# DMASS0_INTAGGR_0_INTAGGR_UNMAP register map
Vendor: Texas Instruments
Peripheral module from a debugger description file (folder am243x).
Registers are 64-bit, read-write, reset 0xFFFF unless marked. A register's access mark holds for its fields unless they carry their own. Offsets are as the file gives them; lines under a group give offsets from that group; [hi:lo] are bit positions; {n}, {i} and the like mark numbered series; 'fields as' and 'values as' point back to an identical list; <NAME> marks a mode.

## DMASS0_INTAGGR_0_INTAGGR_UNMAP
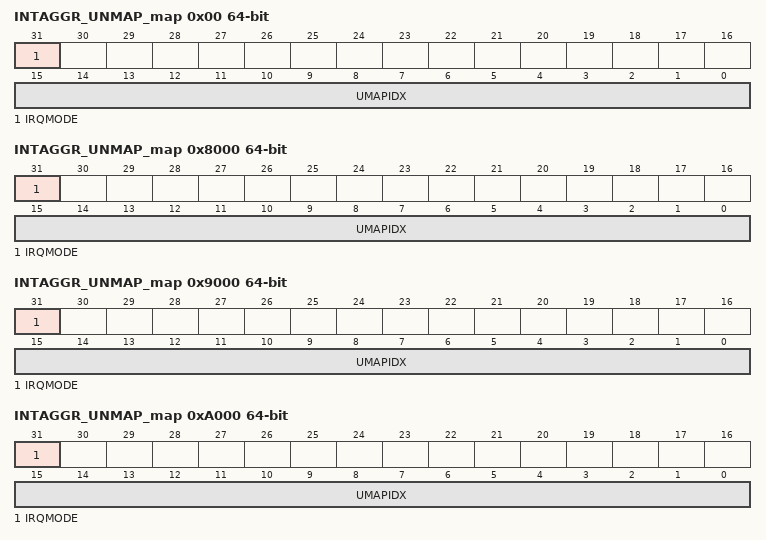
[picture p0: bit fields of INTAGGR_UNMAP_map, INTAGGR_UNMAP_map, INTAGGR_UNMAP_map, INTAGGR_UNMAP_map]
0x00 INTAGGR_UNMAP_map — The Global Event Mapping register controls the egress global event index for this unmapped event. This register may also be optionally used to directly set an interrupt status bit by using the irqmode flag.
  [31] IRQMODE — IRQ Mode Flag. When set, this register act like a mapper with bitnum in 5:0 and regnum in 14:6.
  [15:0] UMAPIDX — Global event index. This field specifies the index of the outgoing global event. Set to 0xFFFF to disable.
0x8000 INTAGGR_UNMAP_map — The Global Event Mapping register controls the egress global event index for this unmapped event. This register may also be optionally used to directly set an interrupt status bit by using the irqmode flag.
  fields as INTAGGR_UNMAP_map
0x9000 INTAGGR_UNMAP_map — The Global Event Mapping register controls the egress global event index for this unmapped event. This register may also be optionally used to directly set an interrupt status bit by using the irqmode flag.
  fields as INTAGGR_UNMAP_map
0xA000 INTAGGR_UNMAP_map — The Global Event Mapping register controls the egress global event index for this unmapped event. This register may also be optionally used to directly set an interrupt status bit by using the irqmode flag.
  fields as INTAGGR_UNMAP_map
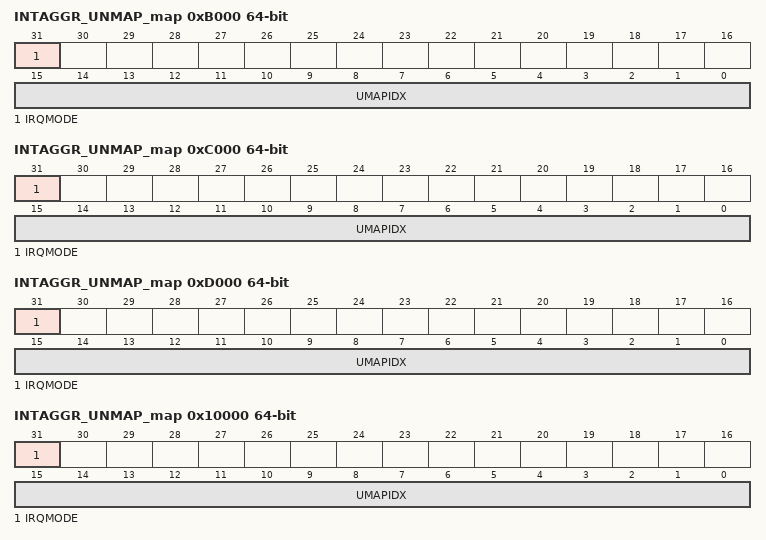
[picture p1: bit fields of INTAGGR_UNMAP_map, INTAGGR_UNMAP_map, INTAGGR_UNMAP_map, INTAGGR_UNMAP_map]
0xB000 INTAGGR_UNMAP_map — The Global Event Mapping register controls the egress global event index for this unmapped event. This register may also be optionally used to directly set an interrupt status bit by using the irqmode flag.
  fields as INTAGGR_UNMAP_map
0xC000 INTAGGR_UNMAP_map — The Global Event Mapping register controls the egress global event index for this unmapped event. This register may also be optionally used to directly set an interrupt status bit by using the irqmode flag.
  fields as INTAGGR_UNMAP_map
0xD000 INTAGGR_UNMAP_map — The Global Event Mapping register controls the egress global event index for this unmapped event. This register may also be optionally used to directly set an interrupt status bit by using the irqmode flag.
  fields as INTAGGR_UNMAP_map
0x10000 INTAGGR_UNMAP_map — The Global Event Mapping register controls the egress global event index for this unmapped event. This register may also be optionally used to directly set an interrupt status bit by using the irqmode flag.
  fields as INTAGGR_UNMAP_map
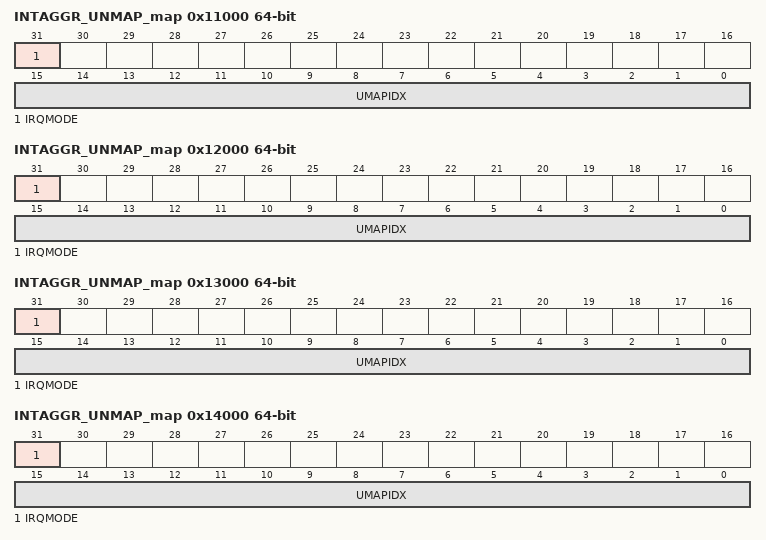
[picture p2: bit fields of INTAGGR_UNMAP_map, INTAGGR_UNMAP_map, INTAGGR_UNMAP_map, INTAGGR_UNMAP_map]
0x11000 INTAGGR_UNMAP_map — The Global Event Mapping register controls the egress global event index for this unmapped event. This register may also be optionally used to directly set an interrupt status bit by using the irqmode flag.
  fields as INTAGGR_UNMAP_map
0x12000 INTAGGR_UNMAP_map — The Global Event Mapping register controls the egress global event index for this unmapped event. This register may also be optionally used to directly set an interrupt status bit by using the irqmode flag.
  fields as INTAGGR_UNMAP_map
0x13000 INTAGGR_UNMAP_map — The Global Event Mapping register controls the egress global event index for this unmapped event. This register may also be optionally used to directly set an interrupt status bit by using the irqmode flag.
  fields as INTAGGR_UNMAP_map
0x14000 INTAGGR_UNMAP_map — The Global Event Mapping register controls the egress global event index for this unmapped event. This register may also be optionally used to directly set an interrupt status bit by using the irqmode flag.
  fields as INTAGGR_UNMAP_map
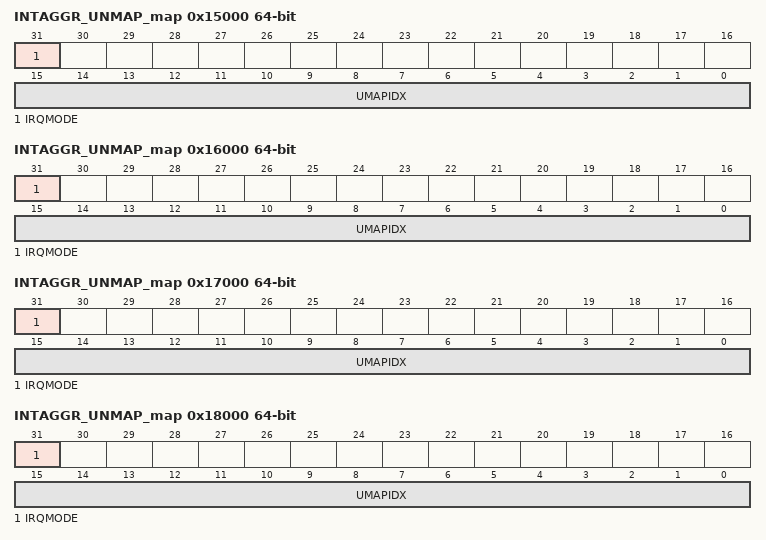
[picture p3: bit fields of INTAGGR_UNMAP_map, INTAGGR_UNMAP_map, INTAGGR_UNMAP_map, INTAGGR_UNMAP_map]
0x15000 INTAGGR_UNMAP_map — The Global Event Mapping register controls the egress global event index for this unmapped event. This register may also be optionally used to directly set an interrupt status bit by using the irqmode flag.
  fields as INTAGGR_UNMAP_map
0x16000 INTAGGR_UNMAP_map — The Global Event Mapping register controls the egress global event index for this unmapped event. This register may also be optionally used to directly set an interrupt status bit by using the irqmode flag.
  fields as INTAGGR_UNMAP_map
0x17000 INTAGGR_UNMAP_map — The Global Event Mapping register controls the egress global event index for this unmapped event. This register may also be optionally used to directly set an interrupt status bit by using the irqmode flag.
  fields as INTAGGR_UNMAP_map
0x18000 INTAGGR_UNMAP_map — The Global Event Mapping register controls the egress global event index for this unmapped event. This register may also be optionally used to directly set an interrupt status bit by using the irqmode flag.
  fields as INTAGGR_UNMAP_map
